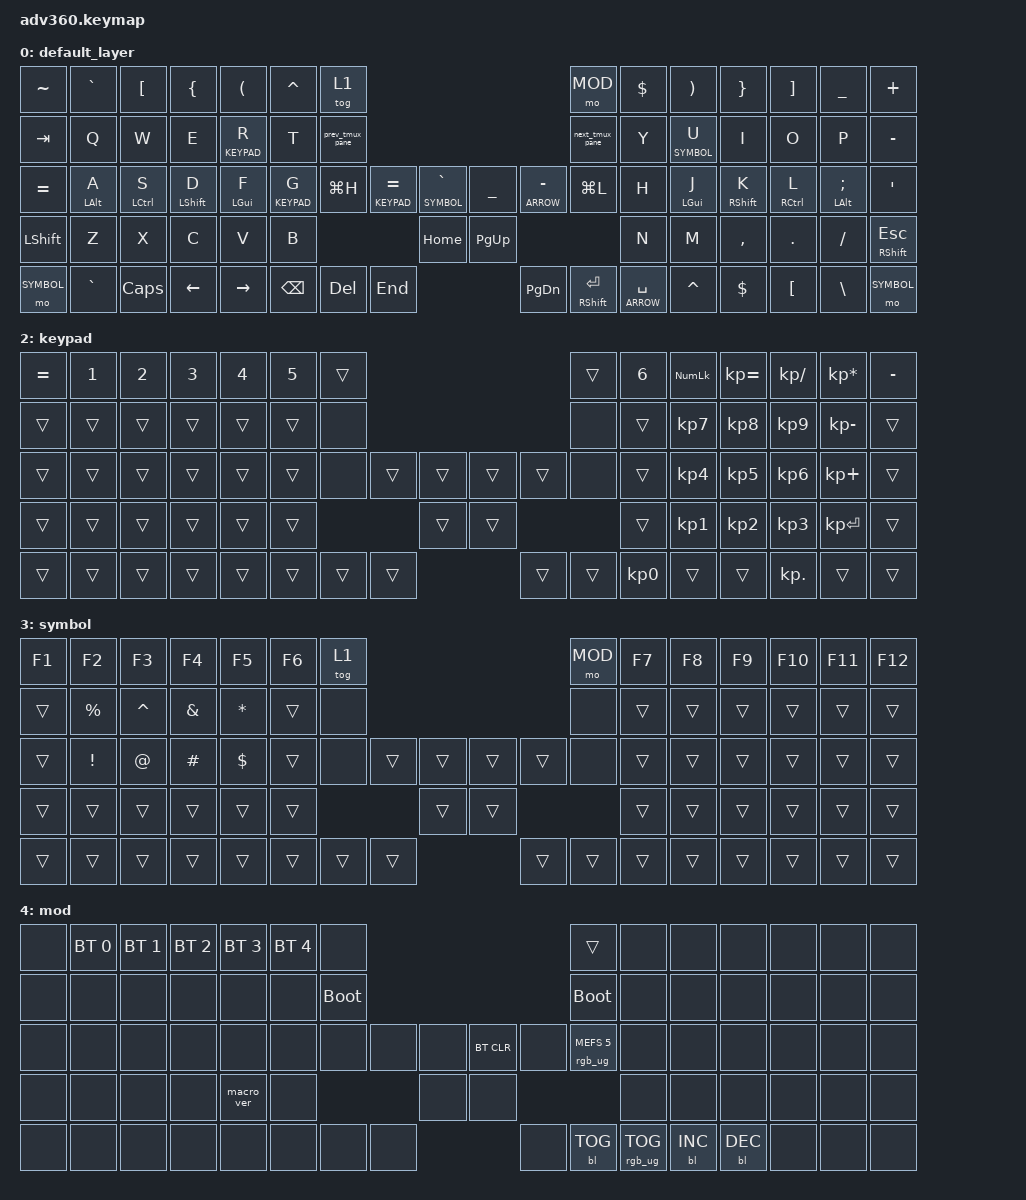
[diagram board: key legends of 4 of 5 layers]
#include <behaviors.dtsi>
#include <dt-bindings/zmk/keys.h>
#include <dt-bindings/zmk/bt.h>
#include <dt-bindings/zmk/rgb.h>
#include <dt-bindings/zmk/backlight.h>

/ {
    behaviors {
      #include "macros.dtsi"
      #include "version.dtsi"
      #ifndef VERSION_MACRO
      macro_ver: macro_ver {
        compatible = "zmk,behavior-macro";
        label = "macro_version";
        #binding-cells = <0>;
        bindings = <&kp RET>;
      };
      #endif

      hm: homerow_mods {
          compatible = "zmk,behavior-hold-tap";
          label = "HOMEROW_MODS";
          #binding-cells = <2>;
          tapping-term-ms = <150>;
          quick_tap_ms = <125>;
          flavor = "tap-preferred";
          bindings = <&kp>, <&kp>;
      };
      shm: slow_homerow_mods {
          compatible = "zmk,behavior-hold-tap";
          label = "SLOW_HOMEROW_MODS";
          #binding-cells = <2>;
          tapping-term-ms = <250>;
          quick_tap_ms = <200>;
          flavor = "tap-preferred";
          bindings = <&kp>, <&kp>;
      };
    };

    macros {
        next_tmux_pane: next_tmux_pane {
            compatible = "zmk,behavior-macro";
            #binding-cells = <0>;
            bindings
                = <&macro_press &kp LGUI>
                , <&macro_tap &kp SPACE &kp L>
                , <&macro_release &kp LGUI>
                ;
        };
        prev_tmux_pane: prev_tmux_pane {
            compatible = "zmk,behavior-macro";
            #binding-cells = <0>;
            bindings
                = <&macro_press &kp LGUI>
                , <&macro_tap &kp SPACE &kp H>
                , <&macro_release &kp LGUI>
                ;
        };
    };

    // Home row mods
    #define _F_CMD &hm LGUI F   // Command on index fingers
    #define _J_CMD &hm LGUI J
    #define _D_SFT &hm LSHFT D  // Shift on middle fingers
    #define _K_SFT &hm RSHFT K
    #define _S_CTL &hm LCTRL S  // Control on ring fingers
    #define _L_CTL &hm RCTRL L
    #define _A_OPT &shm LALT A   // Option on pinky fingers
    #define _SEMI_OPT &shm LALT SEMI
    
    #define DEFAULT 0
    #define ARROW   1
    #define KEYPAD  2
    #define SYMBOL  3
    #define MOD     4

  // TODO: Remove keypad hold from G

  keymap {
    compatible = "zmk,keymap";

    default_layer {
      bindings = <
        &kp TILDE &kp GRAVE &kp LEFT_BRACKET &kp LEFT_BRACE &kp LEFT_PARENTHESIS &kp CARET &tog 1                                                                                     &mo MOD &kp DOLLAR &kp RIGHT_PARENTHESIS &kp RIGHT_BRACE    &kp RIGHT_BRACKET   &kp UNDER   &kp PLUS
        &kp TAB   &kp Q     &kp W    &kp E    &lt KEYPAD R      &kp T  &prev_tmux_pane                                                                                                              &next_tmux_pane &kp Y &lt SYMBOL U &kp I &kp O &kp P    &kp MINUS
        &kp EQUAL   _A_OPT     _S_CTL    _D_SFT    _F_CMD      &lt KEYPAD G  &kp LG(H)                    &lt KEYPAD EQUAL &lt SYMBOL GRAVE &kp UNDER  &lt ARROW MINUS                         &kp LG(L) &kp H  _J_CMD  _K_SFT     _L_CTL    _SEMI_OPT &kp SQT
        &kp LSHFT &kp Z     &kp X    &kp C    &kp V      &kp B                                                                   &kp HOME &kp PG_UP                                          &kp N  &kp M  &kp COMMA &kp DOT &kp FSLH &hm RSHFT ESC
        &mo SYMBOL     &kp GRAVE &kp CAPS &kp LEFT &kp RIGHT                                                     &kp BSPC &kp DEL &kp END &kp PG_DN &hm RSHFT ENTER &lt ARROW SPACE                 &kp CARET &kp DOLLAR  &kp LEFT_BRACKET  &kp BSLH &mo SYMBOL
      >;
    };
    arrow {
      bindings = <
        &kp F1 &kp F2 &kp F3 &kp F4 &kp F5 &kp F6 &tog 1                                           &mo MOD &kp F7 &kp F8 &kp F9 &kp F10 &kp F11 &kp F12
        &trans &trans &kp &trans &kp &trans &trans &trans  &none                                           &none &trans &kp &trans &kp &trans &trans  &trans  &trans
        &trans &trans &kp &trans &kp &trans &kp &trans &trans  &none        &trans &trans &trans &trans        &none &kp LEFT_ARROW &kp DOWN_ARROW &kp UP_ARROW &kp RIGHT_ARROW  &trans  &trans
        &trans &trans &kp &trans &kp &trans &kp &trans &trans                      &trans &trans                     &trans &kp &trans &kp &trans  &trans  &trans &trans
        &trans &trans &trans &trans &trans               &trans &trans &trans &trans &trans &trans              &trans &trans &trans  &trans  &trans
      >;
    };
    keypad {
      bindings = <
        &kp EQUAL &kp N1    &kp N2   &kp N3   &kp N4     &kp N5 &trans                                      &trans &kp N6 &kp KP_NUM &kp KP_EQUAL &kp KP_DIVIDE &kp KP_MULTIPLY &kp MINUS
        &trans &trans &trans &trans &trans &trans  &none                                                    &none &trans  &kp KP_N7  &kp KP_N8    &kp KP_N9     &kp KP_MINUS    &trans
        &trans &trans &trans &trans &trans &trans  &none               &trans &trans &trans &trans           &none &trans  &kp KP_N4  &kp KP_N5    &kp KP_N6     &kp KP_PLUS     &trans
        &trans &trans &trans &trans &trans &trans                            &trans &trans                           &trans  &kp KP_N1  &kp KP_N2    &kp KP_N3     &kp KP_ENTER    &trans
        &trans &trans &trans &trans &trans                   &trans &trans &trans &trans &trans &kp KP_N0              &trans     &trans     &kp KP_DOT    &trans        &trans
      >;
    };
    symbol {
      bindings = <
        &kp F1 &kp F2 &kp F3 &kp F4 &kp F5 &kp F6 &tog 1                                           &mo MOD &kp F7 &kp F8 &kp F9 &kp F10 &kp F11 &kp F12
        &trans &kp PERCENT &kp CARET &kp AMPERSAND &kp ASTERISK &trans  &none                                           &none &trans &trans &trans &trans  &trans  &trans
        &trans &kp EXCLAMATION &kp AT &kp HASH &kp DOLLAR &trans  &none        &trans &trans &trans &trans        &none &trans &trans &trans &trans &trans  &trans
        &trans &trans &trans &trans &trans &trans                      &trans &trans                     &trans &trans &trans &trans &trans &trans
        &trans &trans &trans &trans &trans               &trans &trans &trans &trans &trans &trans              &trans &trans &trans  &trans  &trans
      >;
    };
    mod {
      bindings = <
        &none &bt BT_SEL 0 &bt BT_SEL 1 &bt BT_SEL 2 &bt BT_SEL 3 &bt BT_SEL 4 &none                                                                     &trans                 &none        &none        &none        &none &none &none
        &none &none        &none        &none        &none        &none        &bootloader                                                               &bootloader            &none        &none        &none        &none &none &none
        &none &none        &none        &none        &none        &none        &none                   &none &none &bt BT_CLR &none                      &rgb_ug RGB_MEFS_CMD 5 &none        &none        &none        &none &none &none
        &none &none        &none        &none        &macro_ver   &none                                      &none &none                                                        &none        &none        &none        &none &none &none
        &none &none        &none        &none        &none                                       &none &none &none &none      &bl BL_TOG &rgb_ug RGB_TOG                                     &bl BL_INC   &bl BL_DEC   &none &none &none
      >;
    };
  };
};
